# PIC18LF8525 register map
Vendor: Microchip
Registers are 8-bit, read-write, no defined reset value unless marked. A register's access mark holds for its fields unless they carry their own. Addresses are absolute, and some are shared; only a register's first bit layout is shown; [hi:lo] are bit positions; {n}, {i} and the like mark numbered series; 'fields as' and 'values as' point back to an identical list.

## SFR
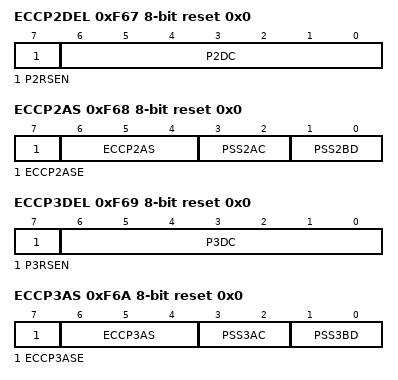
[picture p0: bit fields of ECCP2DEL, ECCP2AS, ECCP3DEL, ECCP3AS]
0xF67 ECCP2DEL reset 0x0
  [7] P2RSEN, [6:0] P2DC
0xF68 ECCP2AS reset 0x0
  [7] ECCP2ASE, [6:4] ECCP2AS, [3:2] PSS2AC, [1:0] PSS2BD
0xF69 ECCP3DEL reset 0x0
  [7] P3RSEN, [6:0] P3DC
0xF6A ECCP3AS reset 0x0
  [7] ECCP3ASE, [6:4] ECCP3AS, [3:2] PSS3AC, [1:0] PSS3BD
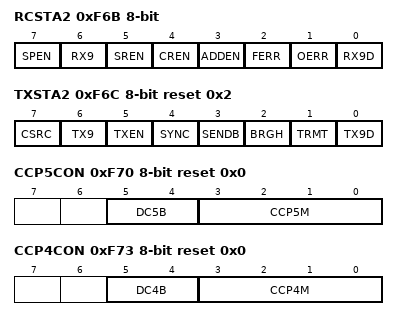
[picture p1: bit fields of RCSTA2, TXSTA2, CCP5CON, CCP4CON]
0xF6B RCSTA2 — (power-on value 0000000x)
  [7] SPEN, [6] RX9, [5] SREN, [4] CREN, [3] ADDEN, [2] FERR ro, [1] OERR ro, [0] RX9D ro
0xF6C TXSTA2 reset 0x2
  [7] CSRC, [6] TX9, [5] TXEN, [4] SYNC, [3] SENDB, [2] BRGH, [1] TRMT ro, [0] TX9D
0xF6D TXREG2 wo reset 0x0
0xF6E RCREG2 ro reset 0x0
0xF6F SPBRG2 reset 0x0
0xF70 CCP5CON reset 0x0
  [5:4] DC5B, [3:0] CCP5M
0xF71 CCPR5L — (power-on value xxxxxxxx)
0xF72 CCPR5H — (power-on value xxxxxxxx)
0xF73 CCP4CON reset 0x0
  [5:4] DC4B, [3:0] CCP4M
0xF74 CCPR4L — (power-on value xxxxxxxx)
0xF75 CCPR4H — (power-on value xxxxxxxx)
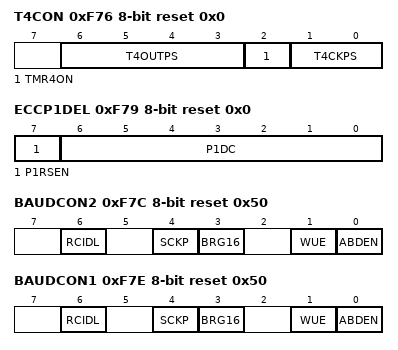
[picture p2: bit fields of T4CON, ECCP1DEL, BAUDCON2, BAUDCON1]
0xF76 T4CON reset 0x0
  [6:3] T4OUTPS, [2] TMR4ON, [1:0] T4CKPS
0xF77 PR4 reset 0xFF
0xF78 TMR4 reset 0x0
0xF79 ECCP1DEL reset 0x0
  [7] P1RSEN, [6:0] P1DC
0xF7C BAUDCON2 reset 0x50
  [6] RCIDL ro, [4] SCKP, [3] BRG16, [1] WUE, [0] ABDEN
0xF7D SPBRGH2 reset 0x0
  [7:0] SPBRGH1
0xF7E BAUDCON1 reset 0x50
  [6] RCIDL ro, [4] SCKP, [3] BRG16, [1] WUE, [0] ABDEN
0xF7F SPBRGH1 reset 0x0
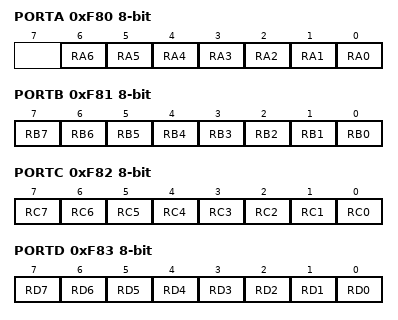
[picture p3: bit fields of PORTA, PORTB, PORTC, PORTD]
0xF80 PORTA — (power-on value -x0x0000)
  [n] RA{n} (n=0..6)
0xF81 PORTB — (power-on value xxxxxxxx)
  [n] RB{n} (n=0..7)
0xF82 PORTC — (power-on value xxxxxxxx)
  [n] RC{n} (n=0..7)
0xF83 PORTD — (power-on value xxxxxxxx)
  [n] RD{n} (n=0..7)
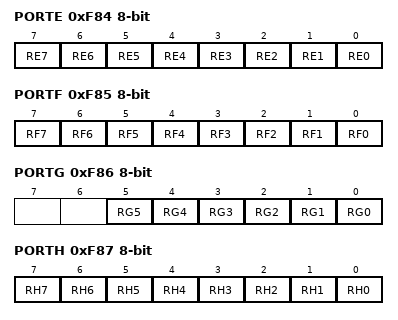
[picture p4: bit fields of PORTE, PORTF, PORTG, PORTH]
0xF84 PORTE — (power-on value xxxxxxxx)
  [n] RE{n} (n=0..7)
0xF85 PORTF — (power-on value x0000000)
  [n] RF{n} (n=0..7)
0xF86 PORTG — (power-on value --xxxxxx)
  [5] RG5 ro, [n] RG{n} (n=0..4)
0xF87 PORTH — (power-on value 0000xxxx)
  [n] RH{n} (n=0..7)
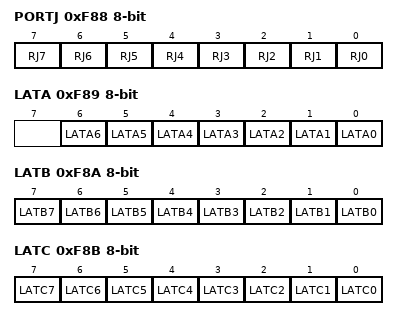
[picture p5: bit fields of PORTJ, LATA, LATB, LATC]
0xF88 PORTJ — (power-on value xxxxxxxx)
  [n] RJ{n} (n=0..7)
0xF89 LATA — (power-on value -xxxxxxx)
  [n] LATA{n} (n=0..6)
0xF8A LATB — (power-on value xxxxxxxx)
  [n] LATB{n} (n=0..7)
0xF8B LATC — (power-on value xxxxxxxx)
  [n] LATC{n} (n=0..7)
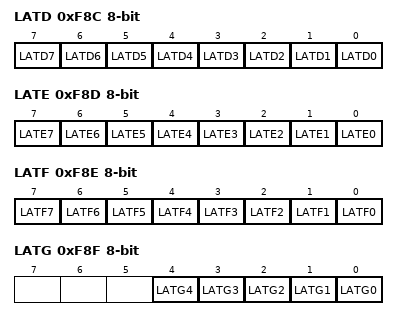
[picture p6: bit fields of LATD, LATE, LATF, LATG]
0xF8C LATD — (power-on value xxxxxxxx)
  [n] LATD{n} (n=0..7)
0xF8D LATE — (power-on value xxxxxxxx)
  [n] LATE{n} (n=0..7)
0xF8E LATF — (power-on value xxxxxxxx)
  [n] LATF{n} (n=0..7)
0xF8F LATG — (power-on value ---xxxxx)
  [n] LATG{n} (n=0..4)
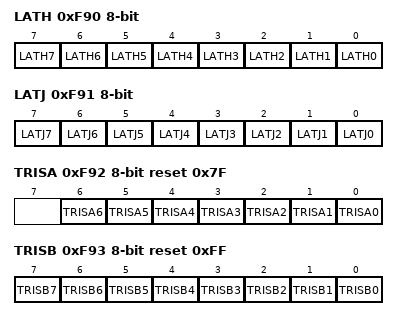
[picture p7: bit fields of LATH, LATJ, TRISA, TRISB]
0xF90 LATH — (power-on value xxxxxxxx)
  [n] LATH{n} (n=0..7)
0xF91 LATJ — (power-on value xxxxxxxx)
  [n] LATJ{n} (n=0..7)
0xF92 TRISA reset 0x7F
  [n] TRISA{n} (n=0..6)
0xF93 TRISB reset 0xFF
  [n] TRISB{n} (n=0..7)
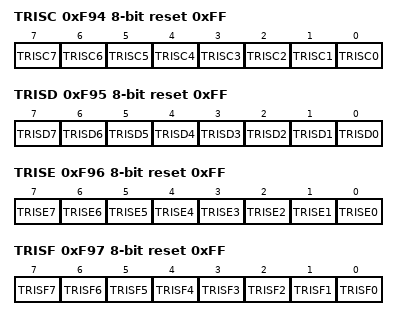
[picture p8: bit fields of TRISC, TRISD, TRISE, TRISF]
0xF94 TRISC reset 0xFF
  [n] TRISC{n} (n=0..7)
0xF95 TRISD reset 0xFF
  [n] TRISD{n} (n=0..7)
0xF96 TRISE reset 0xFF
  [n] TRISE{n} (n=0..7)
0xF97 TRISF reset 0xFF
  [n] TRISF{n} (n=0..7)
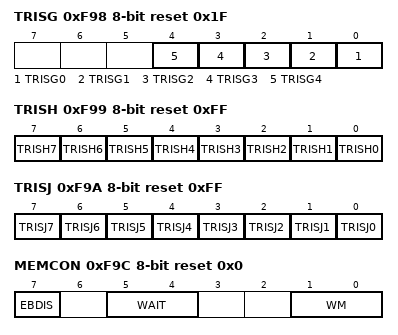
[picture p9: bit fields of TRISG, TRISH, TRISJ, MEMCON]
0xF98 TRISG reset 0x1F
  [n] TRISG{n} (n=0..4)
0xF99 TRISH reset 0xFF
  [n] TRISH{n} (n=0..7)
0xF9A TRISJ reset 0xFF
  [n] TRISJ{n} (n=0..7)
0xF9C MEMCON reset 0x0
  [7] EBDIS, [5:4] WAIT, [1:0] WM
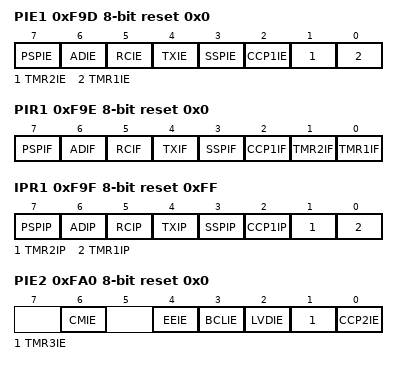
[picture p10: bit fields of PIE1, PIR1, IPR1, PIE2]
0xF9D PIE1 reset 0x0
  [7] PSPIE, [6] ADIE, [5] RCIE, [4] TXIE, [3] SSPIE, [2] CCP1IE, [1] TMR2IE, [0] TMR1IE
0xF9E PIR1 reset 0x0
  [7] PSPIF, [6] ADIF, [5] RCIF ro, [4] TXIF ro, [3] SSPIF, [2] CCP1IF, [1] TMR2IF, [0] TMR1IF
0xF9F IPR1 reset 0xFF
  [7] PSPIP, [6] ADIP, [5] RCIP, [4] TXIP, [3] SSPIP, [2] CCP1IP, [1] TMR2IP, [0] TMR1IP
0xFA0 PIE2 reset 0x0
  [6] CMIE, [4] EEIE, [3] BCLIE, [2] LVDIE, [1] TMR3IE, [0] CCP2IE
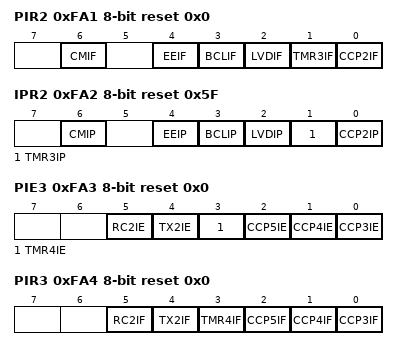
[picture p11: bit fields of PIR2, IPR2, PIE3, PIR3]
0xFA1 PIR2 reset 0x0
  [6] CMIF, [4] EEIF, [3] BCLIF, [2] LVDIF, [1] TMR3IF, [0] CCP2IF
0xFA2 IPR2 reset 0x5F
  [6] CMIP, [4] EEIP, [3] BCLIP, [2] LVDIP, [1] TMR3IP, [0] CCP2IP
0xFA3 PIE3 reset 0x0
  [5] RC2IE, [4] TX2IE, [3] TMR4IE, [2] CCP5IE, [1] CCP4IE, [0] CCP3IE
0xFA4 PIR3 reset 0x0
  [5] RC2IF ro, [4] TX2IF ro, [3] TMR4IF, [2] CCP5IF, [1] CCP4IF, [0] CCP3IF
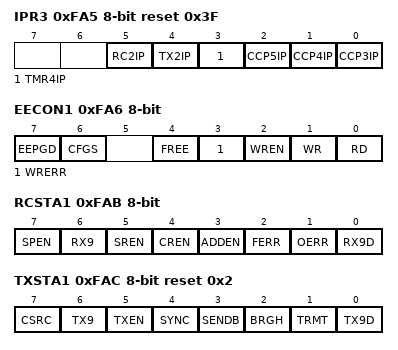
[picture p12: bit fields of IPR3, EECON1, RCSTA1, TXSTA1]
0xFA5 IPR3 reset 0x3F
  [5] RC2IP, [4] TX2IP, [3] TMR4IP, [2] CCP5IP, [1] CCP4IP, [0] CCP3IP
0xFA6 EECON1 — (power-on value xx-0x000)
  [7] EEPGD
  [6] CFGS
  [4] FREE
  [3] WRERR
  [2] WREN
  [1] WR — (can only be set)
  [0] RD — (can only be set)
0xFA7 EECON2 wo
0xFA8 EEDATA reset 0x0
0xFA9 EEADR reset 0x0
0xFAA EEADRH reset 0x0
  [1:0] EEADRH
0xFAB RCSTA1 — (power-on value 0000000x)
  fields as RCSTA2
0xFAC TXSTA1 reset 0x2
  fields as TXSTA2
0xFAD TXREG1 wo reset 0x0
0xFAE RCREG1 ro reset 0x0
0xFAF SPBRG1 reset 0x0
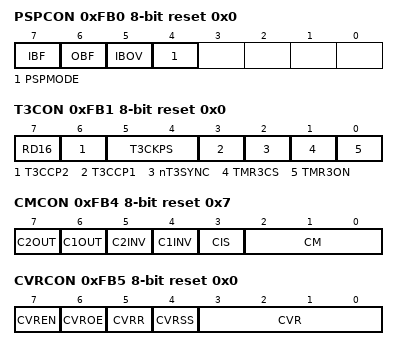
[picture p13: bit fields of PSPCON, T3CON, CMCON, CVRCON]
0xFB0 PSPCON reset 0x0
  [7] IBF, [6] OBF, [5] IBOV, [4] PSPMODE
0xFB1 T3CON reset 0x0
  [7] RD16, [6] T3CCP2, [5:4] T3CKPS, [3] T3CCP1, [2] nT3SYNC, [1] TMR3CS, [0] TMR3ON
0xFB2 TMR3L — (power-on value xxxxxxxx)
0xFB3 TMR3H — (power-on value xxxxxxxx)
0xFB4 CMCON reset 0x7
  [7] C2OUT ro, [6] C1OUT ro, [5] C2INV, [4] C1INV, [3] CIS, [2:0] CM
0xFB5 CVRCON reset 0x0
  [7] CVREN, [6] CVROE, [5] CVRR, [4] CVRSS, [3:0] CVR
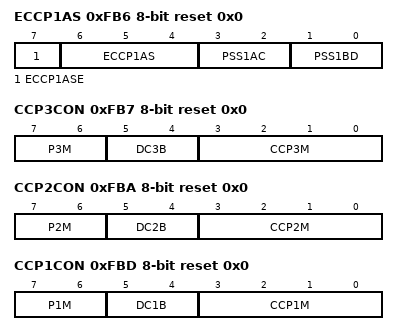
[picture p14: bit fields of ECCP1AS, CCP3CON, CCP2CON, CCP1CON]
0xFB6 ECCP1AS reset 0x0
  [7] ECCP1ASE, [6:4] ECCP1AS, [3:2] PSS1AC, [1:0] PSS1BD
0xFB7 CCP3CON reset 0x0
  [7:6] P3M, [5:4] DC3B, [3:0] CCP3M
0xFB8 CCPR3L — (power-on value xxxxxxxx)
0xFB9 CCPR3H — (power-on value xxxxxxxx)
0xFBA CCP2CON reset 0x0
  [7:6] P2M, [5:4] DC2B, [3:0] CCP2M
0xFBB CCPR2L — (power-on value xxxxxxxx)
0xFBC CCPR2H — (power-on value xxxxxxxx)
0xFBD CCP1CON reset 0x0
  [7:6] P1M, [5:4] DC1B, [3:0] CCP1M
0xFBE CCPR1L — (power-on value xxxxxxxx)
0xFBF CCPR1H — (power-on value xxxxxxxx)
0xFC0 ADCON2 reset 0x0
  [7] ADFM, [5:3] ACQT, [2:0] ADCS
0xFC1 ADCON1 reset 0x0
  [5:4] VCFG, [3:0] PCFG
0xFC2 ADCON0 reset 0x0
  [5:2] CHS, [1] GO_nDONE, [0] ADON
0xFC3 ADRESL — (power-on value xxxxxxxx)
0xFC4 ADRESH — (power-on value xxxxxxxx)
0xFC5 SSPCON2 reset 0x0
  [7] GCEN, [6] ACKSTAT, [5] ACKDT, [4] ACKEN, [3] RCEN, [2] PEN, [1] RSEN, [0] SEN
0xFC6 SSPCON1 reset 0x0
  [7] WCOL, [6] SSPOV, [5] SSPEN, [4] CKP, [3:0] SSPM
0xFC7 SSPSTAT reset 0x0
  [7] SMP, [6] CKE, [5] D_nA, [4] P, [3] S, [2] R_nW, [1] UA, [0] BF
0xFC8 SSPADD reset 0x0
0xFC9 SSPBUF — (power-on value xxxxxxxx)
0xFCA T2CON reset 0x0
  [6:3] TOUTPS, [2] TMR2ON, [1:0] T2CKPS
0xFCB PR2 reset 0xFF
0xFCC TMR2 reset 0x0
0xFCD T1CON reset 0x0
  [7] RD16, [5:4] T1CKPS, [3] T1OSCEN, [2] nT1SYNC, [1] TMR1CS, [0] TMR1ON
0xFCE TMR1L — (power-on value xxxxxxxx)
0xFCF TMR1H — (power-on value xxxxxxxx)
0xFD0 RCON — (power-on value 0--111qq)
  [7] IPEN, [4] nRI, [3] nTO, [2] nPD, [1] nPOR, [0] nBOR
0xFD1 WDTCON reset 0x0
  [0] SWDTEN
0xFD2 LVDCON reset 0x5
  [5] IRVST, [4] LVDEN, [3:0] LVDL
0xFD3 OSCCON reset 0x0
  [3] LOCK, [2] PLLEN, [1:0] SCS
0xFD5 T0CON reset 0xFF
  [7] TMR0ON, [6] T08BIT, [5] T0CS, [4] T0SE, [3] PSA, [2:0] T0PS
0xFD6 TMR0L — (power-on value xxxxxxxx)
0xFD7 TMR0H reset 0x0
0xFD8 STATUS — (power-on value ---xxxxx)
  [4] N, [3] OV, [2] Z, [1] DC, [0] C
0xFD9 FSR2L — (power-on value xxxxxxxx)
0xFDA FSR2H reset 0x0
  [3:0] FSR2H
0xFDB PLUSW2 access not given
0xFDC PREINC2 access not given
0xFDD POSTDEC2 access not given
0xFDE POSTINC2 access not given
0xFDF INDF2 access not given
0xFE0 BSR reset 0x0
  [3:0] BSR
0xFE1 FSR1L — (power-on value xxxxxxxx)
0xFE2 FSR1H reset 0x0
  [3:0] FSR1H
0xFE3 PLUSW1 access not given
0xFE4 PREINC1 access not given
0xFE5 POSTDEC1 access not given
0xFE6 POSTINC1 access not given
0xFE7 INDF1 access not given
0xFE8 WREG — (power-on value xxxxxxxx)
0xFE9 FSR0L — (power-on value xxxxxxxx)
0xFEA FSR0H reset 0x0
  [3:0] FSR0H
0xFEB PLUSW0 access not given
0xFEC PREINC0 access not given
0xFED POSTDEC0 access not given
0xFEE POSTINC0 access not given
0xFEF INDF0 access not given
0xFF0 INTCON3 reset 0xC0
  [7] INT2IP, [6] INT1IP, [5] INT3IE, [4] INT2IE, [3] INT1IE, [2] INT3IF, [1] INT2IF, [0] INT1IF
0xFF1 INTCON2 reset 0xFF
  [7] nRBPU, [6-n] INTEDG{n} (n=0..3), [2] TMR0IP, [1] INT3IP, [0] RBIP
0xFF2 INTCON — (power-on value 0000000x)
  [7] GIE_GIEH, [6] PEIE_GIEL, [5] TMR0IE, [4] INT0IE, [3] RBIE, [2] TMR0IF, [1] INT0IF, [0] RBIF
0xFF3 PRODL — (power-on value xxxxxxxx)
0xFF4 PRODH — (power-on value xxxxxxxx)
0xFF5 TABLAT reset 0x0
0xFF6 TBLPTRL reset 0x0
0xFF7 TBLPTRH reset 0x0
0xFF8 TBLPTRU reset 0x0
  [5] ACSS, [4:0] TBLPTRU
0xFF9 PCL reset 0x0
0xFFA PCLATH reset 0x0
  [7:0] PCH
0xFFB PCLATU reset 0x0
  [4:0] PCU
0xFFC STKPTR reset 0x0
  [7] STKFUL — (can only be cleared)
  [6] STKUNF — (can only be cleared)
  [4:0] STKPTR
0xFFD TOSL reset 0x0
0xFFE TOSH reset 0x0
0xFFF TOSU reset 0x0
  [4:0] TOSU
